# STM32G431xx register map
File version: 1.0
Registers are 32-bit, read-write, reset 0x0 unless marked. A register's access mark holds for its fields unless they carry their own. Offsets are from the block's base; [hi:lo] are bit positions; {n}, {i} and the like mark numbered series.

## IWDG — Independent WATCHDOG
Base 0x40003000
0x00 KR — IWDG Key register
  [15:0] KEY — Key value (write only, read 0000h)
0x04 PR — IWDG Prescaler register
  [2:0] PR — PR[2:0] (Prescaler divider)
0x08 RLR — IWDG Reload register
  [11:0] RL — Watchdog counter reload value
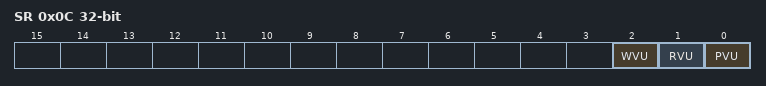
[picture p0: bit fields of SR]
0x0C SR — IWDG Status register
  [2] WVU — Watchdog counter window value update
  [1] RVU — Watchdog counter reload value update
  [0] PVU — Watchdog prescaler value update
0x10 WINR — IWDG Window register
  [11:0] WIN — Watchdog counter window value

## USB — Universal Serial Bus Full Speed Device
Base 0x40005C00
{0x0+4i} EP{i}R 16-bit (i=0..7) — USB Endpoint {i} register
0x40 CNTR 16-bit — Control register
0x44 ISTR 16-bit — Interrupt status register
0x48 FNR 16-bit — Frame number register
0x4C DADDR 16-bit — Device address register
0x50 BTABLE 16-bit — Buffer Table address register
0x54 LPMCSR 16-bit — LPM Control and Status register
0x58 BCDR 16-bit — Battery Charging detector register

## FDCAN_CONFIG — FD Controller Area Network Configuration
Base 0x40006500
0x00 CKDIV — FDCAN clock divider register
  [3:0] PDIV — Input Clock Divider

## PWR — Power Control
Base 0x40007000
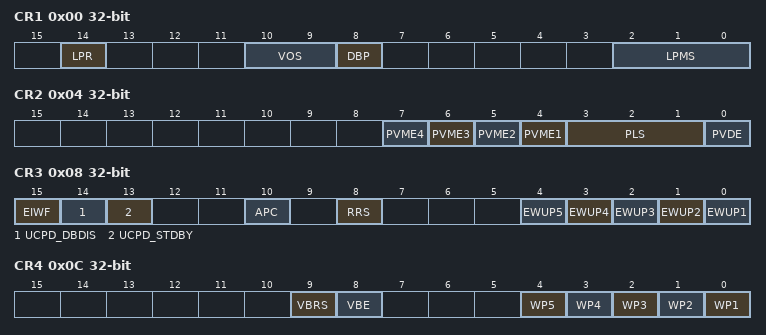
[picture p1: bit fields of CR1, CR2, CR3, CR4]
0x00 CR1 — PWR power control register 1
  [14] LPR — Regulator low-power mode
  [10:9] VOS — VOS[1:0] bits (Regulator voltage scaling output selection)
    1=SCALE1; 2=SCALE2
  [8] DBP — Disable Back-up domain Protection
  [2:0] LPMS — Low-power mode selection field
    0=STOP0; 1=STOP1; 3=STANDBY; 4=SHUTDOWN
0x04 CR2 — PWR power control register 2
  [n+3] PVME{n} (n=1..4) — PVM {n} Enable
  [3:1] PLS — PVD level selection
    {v}=PVDLEVEL_{v} (v=0..7)
  [0] PVDE — Power Voltage Detector Enable
0x08 CR3 — PWR power control register 3
  [15] EIWF — Enable Internal Wake-up line
  [14] UCPD_DBDIS — USB Type-C and Power Delivery Dead Battery disable
  [13] UCPD_STDBY — USB Type-C and Power Delivery standby mode
  [10] APC — Apply pull-up and pull-down configuration
  [8] RRS — SRAM2 Retention in Stand-by mode
  [n-1] EWUP{n} (n=1..5) — Enable Wake-Up Pin {n}
0x0C CR4 — PWR power control register 4
  [9] VBRS — VBAT Battery charging Resistor Selection
    0=CHARG_RESISTOR_5K; 1=CHARGRESISTOR_1_5K
  [8] VBE — VBAT Battery charging Enable
  [n-1] WP{n} (n=1..5) — Wake-Up Pin {n} polarity
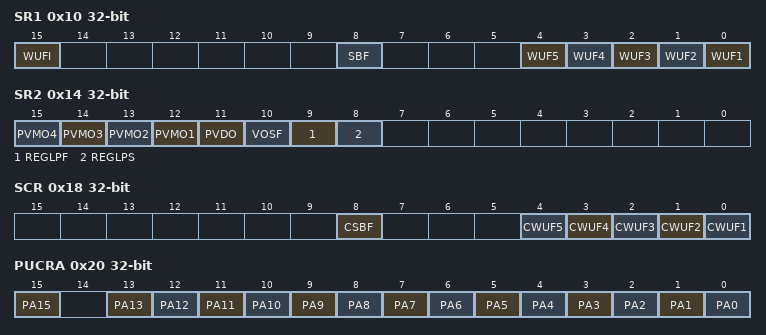
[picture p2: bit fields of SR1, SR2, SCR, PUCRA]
0x10 SR1 — PWR power status register 1
  [15] WUFI — Wake-Up Flag Internal
  [8] SBF — Stand-By Flag
  [n-1] WUF{n} (n=1..5) — Wake-up Flag {n}
0x14 SR2 — PWR power status register 2
  [n+11] PVMO{n} (n=1..4) — Peripheral Voltage Monitoring Output {n}
  [11] PVDO — Power Voltage Detector Output
  [10] VOSF — Voltage Scaling Flag
  [9] REGLPF — Low-power Regulator Flag
  [8] REGLPS — Low-power Regulator Started
0x18 SCR — PWR power status reset register
  [8] CSBF — Clear Stand-By Flag
  [n-1] CWUF{n} (n=1..5) — Clear Wake-up Flag {n}
0x20 PUCRA — Pull_up control register of portA
  [15] PA15 — Port PA15 Pull-Up set
  [n] PA{n} (n=0..13) — Port PA{n} Pull-Up set
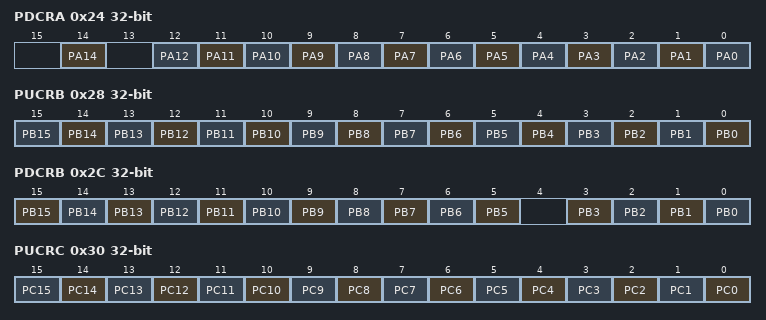
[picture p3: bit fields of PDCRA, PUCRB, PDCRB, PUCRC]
0x24 PDCRA — Pull_Down control register of portA
  [14] PA14 — Port PA14 Pull-Down set
  [n] PA{n} (n=0..12) — Port PA{n} Pull-Down set
0x28 PUCRB — Pull_up control register of portB
  [n] PB{n} (n=0..15) — Port PB{n} Pull-Up set
0x2C PDCRB — Pull_Down control register of portB
  [n] PB{n} (n=5..15) — Port PB{n} Pull-Down set
  [n] PB{n} (n=0..3) — Port PB{n} Pull-Down set
0x30 PUCRC — Pull_up control register of portC
  [n] PC{n} (n=0..15) — Port PC{n} Pull-Up set
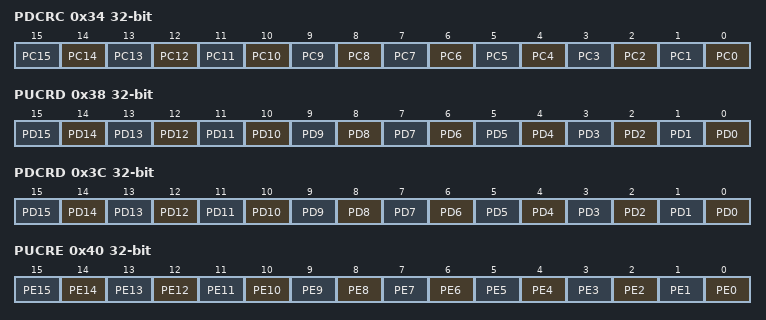
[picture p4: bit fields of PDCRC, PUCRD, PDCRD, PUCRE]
0x34 PDCRC — Pull_Down control register of portC
  [n] PC{n} (n=0..15) — Port PC{n} Pull-Down set
0x38 PUCRD — Pull_up control register of portD
  [n] PD{n} (n=0..15) — Port PD{n} Pull-Up set
0x3C PDCRD — Pull_Down control register of portD
  [n] PD{n} (n=0..15) — Port PD{n} Pull-Down set
0x40 PUCRE — Pull_up control register of portE
  [n] PE{n} (n=0..15) — Port PE{n} Pull-Up set
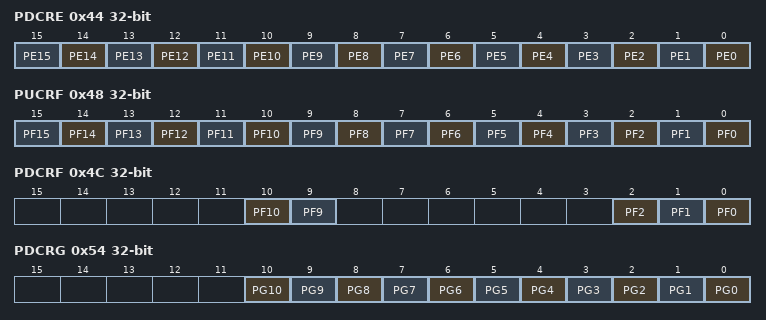
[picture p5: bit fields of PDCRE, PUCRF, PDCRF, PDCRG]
0x44 PDCRE — Pull_Down control register of portE
  [n] PE{n} (n=0..15) — Port PE{n} Pull-Down set
0x48 PUCRF — Pull_up control register of portF
  [n] PF{n} (n=0..15) — Port PF{n} Pull-Up set
0x4C PDCRF — Pull_Down control register of portF
  [10] PF10 — Port PF10 Pull-Down set
  [9] PF9 — Port PF9 Pull-Down set
  [2] PF2 — Port PF2 Pull-Down set
  [1] PF1 — Port PF1 Pull-Down set
  [0] PF0 — Port PF0 Pull-Down set
0x50 PUCRG — Pull_up control register of portG
  [10] PG10 — Port PG10 Pull-Up set
0x54 PDCRG — Pull_Down control register of portG
  [n] PG{n} (n=0..10) — Port PG{n} Pull-Down set
0x80 CR5 — PWR power control register 5
  [8] R1MODE — selection for Main Regulator in Range1
